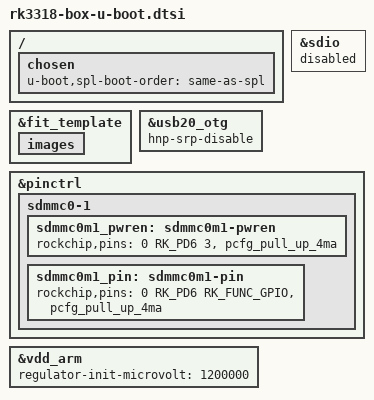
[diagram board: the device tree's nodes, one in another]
// SPDX-License-Identifier: GPL-2.0+
/*
 * (C) Copyright 2020 Armbian project (jock)
 */

#include "rk3328-u-boot.dtsi"
#include "rk3328-sdram-ddr3-666.dtsi"

/*
 * Remove the OP-TEE binary node from the binman assembly to avoid
 * the relative u-boot warning. rk3318-box has not op-tee binary.
 * The absolute path of the offending binary is: 
 * 	/binman/simple-bin/fit/images/@tee-SEQ/tee-os
 *
 * see rockchip-u-boot.dtsi for the binman mayhem
 * 
 */
&fit_template {
	images {
		/delete-node/ @tee-SEQ;
	};
};

/ {
	chosen {
		u-boot,spl-boot-order = "same-as-spl", &sdmmc, &sdmmc_ext, &emmc;
	};

};

/*
&usb_host0_xhci {
	vbus-supply = <&vcc_host_vbus>;
	status = "okay";
};
*/

&usb20_otg {
	hnp-srp-disable;
};

&sdio {
	status="disabled";
};

&pinctrl {

	sdmmc0-1 {
		sdmmc0m1_pwren: sdmmc0m1-pwren {
			rockchip,pins = <0 RK_PD6 3 &pcfg_pull_up_4ma>;
		};

		sdmmc0m1_pin: sdmmc0m1-pin {
			rockchip,pins = <0 RK_PD6 RK_FUNC_GPIO &pcfg_pull_up_4ma>;
		};
	};

};

&vdd_arm {
	regulator-init-microvolt = <1200000>;
};
